# RN821X_RN721X_SOC_V2 register map
File version: v1.0.7
CPU: CM0 r0p0, little endian, no MPU, no FPU, 3 interrupt priority bits
Registers are 32-bit, read-write, reset 0x0 unless marked. A register's access mark holds for its fields unless they carry their own. Offsets are from the block's base; [hi:lo] are bit positions; {n}, {i} and the like mark numbered series.

## DSP — FFT hardware acceleration module
Base 0x40064000
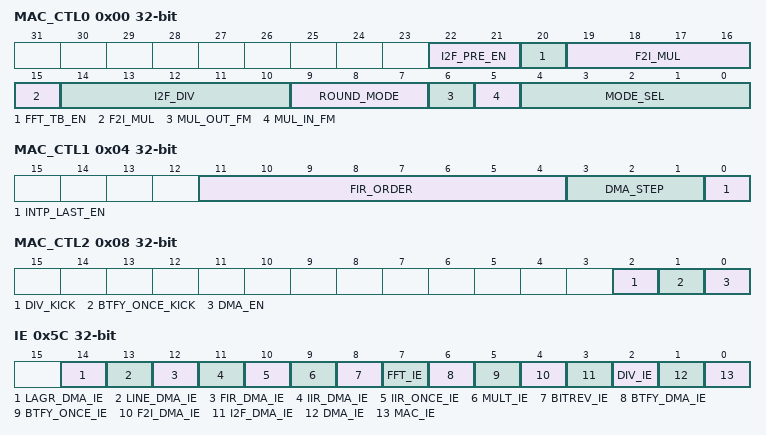
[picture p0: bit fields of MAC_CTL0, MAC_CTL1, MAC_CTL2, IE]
0x00 MAC_CTL0 — MAC unit control register No.0
  [22:21] I2F_PRE_EN — int to float preprocessing selection bits
    0=4BYTE (I2F input data 4 byte available); 1=3BYTE (I2F input data low 3 byte available); 2=2BYTE (I2F input data low 2 byte available); 3=1BYTE (I2F input data low 1 byte available)
  [20] FFT_TB_EN — fft parameter table enable bit(FFT uses a fixed parameter table, only 64 points and 128 points are valid)
  [19:15] F2I_MUL — float to int normalization factor configuration bits(result multiply by 2^n )
  [14:10] I2F_DIV — int to float normalization factor configuration bits(result divide by 2^n )
  [9:7] ROUND_MODE — rounding mode selection bits for float arithmetic
    0=NEARST (float arithmetic rounding mode select as round to nearest); 1=ZERO (float arithmetic rounding mode select as round toward zero); 2=P_INF (float arithmetic rounding mode select as round to positive infinity); 3=N_INF (float arithmetic rounding mode select as round to negative infiinity); 4=UP (float arithmetic rounding mode select as round to nearst up); 5=AWAY (float arithmetic rounding mode select as round away from zero)
  [6] MUL_OUT_FM — FP_MUL(float multiplication) output data format selection bit
    0=FLOAT (select float format); 1=INT (select int format)
  [5] MUL_IN_FM — FP_MUL(float multiplication) input data format selection bit
    0=FLOAT (select float format); 1=INT (select int format)
  [4:0] MODE_SEL — MAC unit mode selection bits
    0=DIS (disable all mode of MAC unit); 1=I2F_ONCE (int to float conversion one-shot mode enable); 2=I2F_DMA (int to float conversion DMA mode enable); 3=F2I_ONCE (float to int conversion one-shot mode enable); 4=F2I_DMA (float to int conversion DMA mode enable); 5=FP_MUL (float multiply mode enable); 6=FP_ADD (float addition mode enable); 7=FP_SUB (float subtraction mode enable); 8=FP_MLAD (float multiplication and addition mode enable); 9=BTFY_ONCE (Butterfly operation unit one-shot mode enable); 10=BTFY_DMA (Butterfly operation unit DMA mode enable); 11=FFT (FFT mode enable); 12=BIT_RV (bit reverse mode enable); 13=IIR_ONCE (2nd IIR filter one-shot mode enable); 14=IIR_DMA (2nd IIR filter DMA mode enable); 15=FIR_DMA (FIR filter mode enable); 16=LINE_INTP (linear interpolation mode enable); 17=LAGR_INTP (Lagrange interpolation mode enable)
0x04 MAC_CTL1 — MAC unit control register No.1
  [11:4] FIR_ORDER — filter order configuration bits
  [3:1] DMA_STEP — step of DMA read data from SRAM configuration bits (only available for IIR/FIR DMA mode )
    {v}=configuration DMA data transfer step as {v+1} (only available for IIR/FIR DMA mode) (v=0..7)
  [0] INTP_LAST_EN — interpolation mode using last data of last period enable bit
0x08 MAC_CTL2 — MAC unit control register No.1
  [2] DIV_KICK wo — The division unit start bit
  [1] BTFY_ONCE_KICK wo — Butterfly operation unit one-shot mode start bit
  [0] DMA_EN — DSP module DMA enable bit(All DMA-related operations of DSP module are started by configuring this bit to 1)
0x0C MAC_IN0 — MAC unit input register No.0
  [31:0] MAC_IN0 — MAC unit input register No.0 bits
0x10 MAC_IN1 — MAC unit input register No.1
  [31:0] MAC_IN1 — MAC unit input register No.1 bits
0x14 MAC_IN2 — MAC unit input register No.2
  [31:0] MAC_IN2 — MAC unit input register No.2 bits
0x18 MAC_IN3 — MAC unit input register No.3
  [31:0] MAC_IN3 — MAC unit input register No.3 bits
0x1C MAC_IN4 — MAC unit input register No.4
  [31:0] MAC_IN4 — MAC unit input register No.4 bits
0x20 MAC_IN5 — MAC unit input register No.5
  [31:0] MAC_IN5 — MAC unit input register No.5 bits
0x24 MAC_OUT0 — MAC unit output register No.0
  [31:0] MAC_OUT0 — MAC unit output register No. bits0
0x28 MAC_OUT1 — MAC unit output register No.1
  [31:0] MAC_OUT1 — MAC unit output register No.1 bits
0x2C MAC_OUT2 — MAC unit output register No.2
  [31:0] MAC_OUT2 — MAC unit output register No.2 bits
0x30 MAC_OUT3 — MAC unit output register No.3
  [31:0] MAC_OUT3 — MAC unit output register No.3 bits
0x34 DIV_IN0 — Division input data register No.0 (dividend)
  [31:0] DIV_IN0 — Division input data register No.0 bits (dividend)
0x38 DIV_IN1 — Division input data register No.1 (divisor)
  [31:0] DIV_IN1 — Division input data register No.1 bits (divisor)
0x3C DIV_OUT0 ro — Division output data register (quotient)
  [31:0] DIV_OUT0 — Division output data register bits (quotient)
0x40 DMA_SRBADR — DMA source data Base address configuration register(different use for different mode, for FFT/BTFY_DMA mode:real part base address)
  [14:0] DMA_SRBADR — DMA source data Base address configuration bits (different use for different mode, for FFT/BTFY_DMA mode:real part base address)
0x44 DMA_SIBADR — DMA source data imaginary part Base address configuration register(for FFT/BTFY_DMA mode)
  [14:0] DMA_SIBADR — DMA source data imaginary part Base address configuration bits (for FFT/BTFY_DMA mode)
0x48 DMA_PRBADR — DMA source data Base address configuration register ( for FFT/BTFY_DMA mode:Base address of the twiddle factors table real part; for FIR DMA mode: parameter a Base address)
  [14:0] DMA_PRBADR — DMA source data Base address configuration bits ( for FFT/BTFY_DMA mode:Base address of the twiddle factors table real part; for FIR DMA mode: parameter a Base address)
0x4C DMA_PIBADR — DMA source data Base address of the twiddle factors table imaginary part (for FFT/BTFY_DMA mode)
  [14:0] DMA_PIBADR
0x50 DMA_TRBADR — DMA target data Base address configuration register (different use for different mode,for FFT/BTFY_DMA mode: DMA target data Base address of FFT real part)
  [14:0] DMA_TRBADR — DMA target data Base address configuration bits (different use for different mode,for FFT/BTFY_DMA mode: DMA target data Base address of FFT real part)
0x54 DMA_TIBADR — DMA target data Base address configuration register (for FFT/BTFY_DMA mode: DMA target data Base address of FFT imaginary part)
  [14:0] DMA_TIBADR — DMA target data Base address configuration bits (for FFT/BTFY_DMA mode: DMA target data Base address of FFT imaginary part)
0x58 DMA_LEN — DMA data length configuration register (different support configuration range for different mode)
  [9:0] DMA_LEN — DMA data length configuration bits (different support configuration range for different mode)
0x5C IE — DSP Interrupt enable register
  [14] LAGR_DMA_IE — Lagrange interpolation interrupt enable bit
  [13] LINE_DMA_IE — linear interpolation interrupt enable bit
  [12] FIR_DMA_IE — FIR DMA interrupt enable bit
  [11] IIR_DMA_IE — IIR DMA interrupt enable bit
  [10] IIR_ONCE_IE — One time IIR interrupt enable bit
  [9] MULT_IE — float multiplication interrupt enable bit
  [8] BITREV_IE — Bit-reverse mode interrupt enable bit
  [7] FFT_IE — FFT Mode interrupt enable bit
  [6] BTFY_DMA_IE — Butterfly DMA interrupt enable bit
  [5] BTFY_ONCE_IE — One time Butterfly interrupt enable bit
  [4] F2I_DMA_IE — float to int interrupt enable bit
  [3] I2F_DMA_IE — int to float interrupt enable bit
  [2] DIV_IE — Division interrupt enable bit
  [1] DMA_IE — DMA done interrupt enable bit
  [0] MAC_IE — MAC unit interrupt enable bit
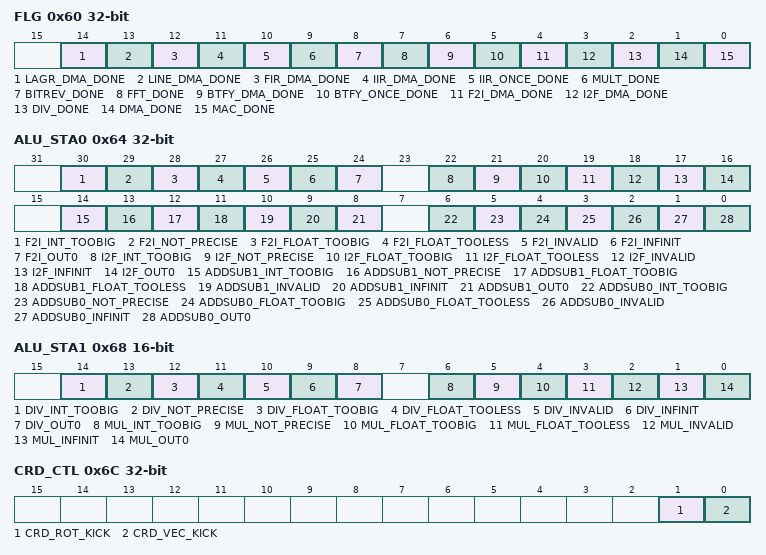
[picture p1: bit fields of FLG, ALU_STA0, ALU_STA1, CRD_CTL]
0x60 FLG write-1-clears — DSP Interrupt flag register
  [14] LAGR_DMA_DONE — Lagrange interpolation interrupt flag
  [13] LINE_DMA_DONE — linear interpolation interrupt flag
  [12] FIR_DMA_DONE — FIR DMA interrupt flag
  [11] IIR_DMA_DONE — IIR DMA interrupt flag
  [10] IIR_ONCE_DONE — One time IIR interrupt flag
  [9] MULT_DONE — float multiplication interrupt flag
  [8] BITREV_DONE — Bit-reverse mode interrupt flag
  [7] FFT_DONE — FFT Mode interrupt flag
  [6] BTFY_DMA_DONE — Butterfly DMA interrupt flag
  [5] BTFY_ONCE_DONE — One time Butterfly interrupt flag
  [4] F2I_DMA_DONE — float to int interrupt flag
  [3] I2F_DMA_DONE — int to float interrupt flag
  [2] DIV_DONE — Division interrupt flag
  [1] DMA_DONE — DMA done interrupt flag
  [0] MAC_DONE — MAC unit interrupt flag
0x64 ALU_STA0 ro — MAC unit status register NO.0
  [30] F2I_INT_TOOBIG — F2I int result after rounding has a magnitude greater than the largest representable two'scomplement integer with the same sign
  [29] F2I_NOT_PRECISE — F2I int or float output is not equal to the infinitely precise result
  [28] F2I_FLOAT_TOOBIG — F2I float number greater than maximum normalized number
  [27] F2I_FLOAT_TOOLESS — F2I float number less than minimum normalized number
  [26] F2I_INVALID — F2I float operation is invalid or one input is NAN
  [25] F2I_INFINIT — F2I float output is infinity
  [24] F2I_OUT0 — F2I int or float output is zero
  [22] I2F_INT_TOOBIG — I2F int result after rounding has a magnitude greater than the largest representable two'scomplement integer with the same sign
  [21] I2F_NOT_PRECISE — I2F int or float output is not equal to the infinitely precise result
  [20] I2F_FLOAT_TOOBIG — I2F float number greater than maximum normalized number
  [19] I2F_FLOAT_TOOLESS — I2F float number less than minimum normalized number
  [18] I2F_INVALID — I2F float operation is invalid or one input is NAN
  [17] I2F_INFINIT — I2F float output is infinity
  [16] I2F_OUT0 — I2F int or float output is zero
  [14] ADDSUB1_INT_TOOBIG — ADDSUB1 int result after rounding has a magnitude greater than the largest representable two'scomplement integer with the same sign
  [13] ADDSUB1_NOT_PRECISE — ADDSUB1 int or float output is not equal to the infinitely precise result
  [12] ADDSUB1_FLOAT_TOOBIG — ADDSUB1 float number greater than maximum normalized number
  [11] ADDSUB1_FLOAT_TOOLESS — ADDSUB1 float number less than minimum normalized number
  [10] ADDSUB1_INVALID — ADDSUB1 float operation is invalid or one input is NAN
  [9] ADDSUB1_INFINIT — ADDSUB1 float output is infinity
  [8] ADDSUB1_OUT0 — ADDSUB1 int or float output is zero
  [6] ADDSUB0_INT_TOOBIG — ADDSUB0 int result after rounding has a magnitude greater than the largest representable two'scomplement integer with the same sign
  [5] ADDSUB0_NOT_PRECISE — ADDSUB0 int or float output is not equal to the infinitely precise result
  [4] ADDSUB0_FLOAT_TOOBIG — ADDSUB0 float number greater than maximum normalized number
  [3] ADDSUB0_FLOAT_TOOLESS — ADDSUB0 float number less than minimum normalized number
  [2] ADDSUB0_INVALID — ADDSUB0 float operation is invalid or one input is NAN
  [1] ADDSUB0_INFINIT — ADDSUB0 float output is infinity
  [0] ADDSUB0_OUT0 — ADDSUB0 int or float output is zero
0x68 ALU_STA1 16-bit ro — MAC unit status register NO.1
  [14] DIV_INT_TOOBIG — DIV int result after rounding has a magnitude greater than the largest representable two'scomplement integer with the same sign
  [13] DIV_NOT_PRECISE — DIV int or float output is not equal to the infinitely precise result
  [12] DIV_FLOAT_TOOBIG — DIV float number greater than maximum normalized number
  [11] DIV_FLOAT_TOOLESS — DIV float number less than minimum normalized number
  [10] DIV_INVALID — DIV float operation is invalid or one input is NAN
  [9] DIV_INFINIT — DIV float output is infinity
  [8] DIV_OUT0 — DIV int or float output is zero
  [6] MUL_INT_TOOBIG — MUL int result after rounding has a magnitude greater than the largest representable two'scomplement integer with the same sign
  [5] MUL_NOT_PRECISE — MUL int or float output is not equal to the infinitely precise result
  [4] MUL_FLOAT_TOOBIG — MUL float number greater than maximum normalized number
  [3] MUL_FLOAT_TOOLESS — MUL float number less than minimum normalized number
  [2] MUL_INVALID — MUL float operation is invalid or one input is NAN
  [1] MUL_INFINIT — MUL float output is infinity
  [0] MUL_OUT0 — MUL int or float output is zero
0x6C CRD_CTL wo — DSP Cordic unit control register
  [1] CRD_ROT_KICK — DSP cordic rotation mode start bit
  [0] CRD_VEC_KICK — DSP cordic vector mode start bit
0x70 CRD_XIN — Cordic Vector mode data x input register
  [31:0] CRD_XIN — Cordic Vector mode data x input
0x74 CRD_YIN — Cordic Vector mode data y input register
  [31:0] CRD_YIN — Cordic Vector mode data y input
0x78 CRD_AMP ro — Cordic Vector mode Amplitude Output register
  [31:0] CRD_AMP — Cordic Vector mode Amplitude Output
0x7C CRD_PHASE ro — Cordic Vector mode Phase Output register
  [31:0] CRD_PHASE — Cordic Vector mode Phase Output
0x80 CRD_ANGLE — Cordic rotation mode input register
  [31:0] CRD_ANGLE — Cordic rotation mode input
0x84 CRD_COS ro — Cordic Vector mode Cosine Output register
  [31:0] CRD_COS — Cordic Vector mode Cosine Output
0x88 CRD_SIN ro — Cordic Vector mode Sine Output register
  [31:0] CRD_SIN — Cordic Vector mode Sine Output
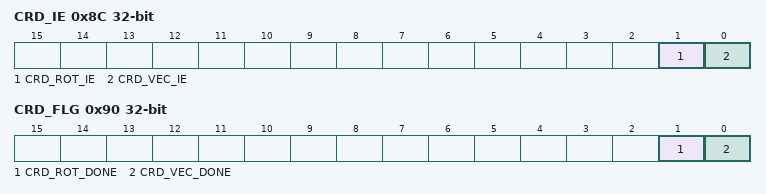
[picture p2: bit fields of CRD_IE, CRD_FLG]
0x8C CRD_IE — Cordic Completion Interrupt enable register
  [1] CRD_ROT_IE — Cordic Rotation Mode Completion Interrupt Enable
  [0] CRD_VEC_IE — Cordic Vector Mode Completion Interrupt Enable
0x90 CRD_FLG write-1-clears — Cordic Completion Interrupt flag register
  [1] CRD_ROT_DONE — Cordic Rotation operation Completion Flag
  [0] CRD_VEC_DONE — Cordic Vector operation Completion Flag
0x94 INTP_LEN — interpolation input data len configuration register
  [12:0] INTP_LEN — interpolation input data len configuration bits
0x98 INTP_LOC — current interpolation location configuration (float format) register
  [31:0] INTP_LOC — current interpolation location configuration (float format) bits
0x9C INTP_STEP — interpolation step configuration (float format) register
  [31:0] INTP_STEP — interpolation step configuration (float format) bits
